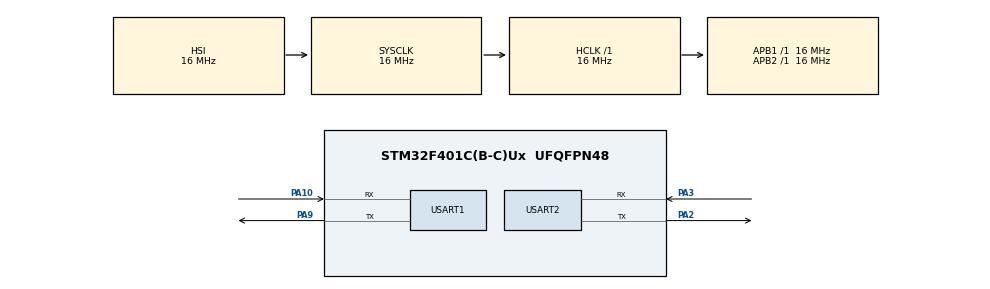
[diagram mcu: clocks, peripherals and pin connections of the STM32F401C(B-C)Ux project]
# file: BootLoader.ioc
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Mcu.Family=STM32F4
Mcu.Name=STM32F401C(B-C)Ux
Mcu.Package=UFQFPN48
NVIC.PriorityGroup=NVIC_PRIORITYGROUP_4
PA10.Mode=Asynchronous
PA10.Signal=USART1_RX
PA2.Mode=Asynchronous
PA2.Signal=USART2_TX
PA3.Mode=Asynchronous
PA3.Signal=USART2_RX
PA9.Mode=Asynchronous
PA9.Signal=USART1_TX
ProjectManager.HeapSize=0x200
ProjectManager.StackSize=0x400
ProjectManager.TargetToolchain=STM32CubeIDE
RCC.AHBFreq_Value=16000000
RCC.APB1Freq_Value=16000000
RCC.APB2Freq_Value=16000000
RCC.CortexFreq_Value=16000000
RCC.HSE_VALUE=25000000
RCC.HSI_VALUE=16000000
RCC.LSE_VALUE=32768
RCC.SYSCLKFreq_VALUE=16000000
RCC.VCOOutputFreq_Value=192000000
USART1.VirtualMode=VM_ASYNC
USART2.VirtualMode=VM_ASYNC
VP_CRC_VS_CRC.Mode=CRC_Activate
board=custom

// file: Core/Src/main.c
/* USER CODE BEGIN Header */
/**
  ******************************************************************************
  * @file           : main.c
  * @brief          : Main program body
  ******************************************************************************
  * @attention
  *
  * Copyright (c) 2024 STMicroelectronics.
  * All rights reserved.
  *
  * This software is licensed under terms that can be found in the LICENSE file
  * in the root directory of this software component.
  * If no LICENSE file comes with this software, it is provided AS-IS.
  *
  ******************************************************************************
  */
/* USER CODE END Header */
#include "main.h"

/* USER CODE BEGIN PM */
#define FLASH_SECTOR2_ADDRESS		0x08008000
/* USER CODE END PM */

CRC_HandleTypeDef hcrc;

UART_HandleTypeDef huart1;
UART_HandleTypeDef huart2;

void SystemClock_Config(void);
static void MX_GPIO_Init(void);
static void MX_CRC_Init(void);
static void MX_USART1_UART_Init(void);
static void MX_USART2_UART_Init(void);

int main(void)
{

  /* USER CODE BEGIN 1 */
	  char fatma[]="FatmaEzzatAbdelaziz\r\n";
	  HAL_Init();

		GPIO_InitTypeDef sw={
					.Pin=GPIO_PIN_1,
					.Mode=GPIO_MODE_INPUT,
					.Pull=GPIO_PULLDOWN,
					.Speed=GPIO_SPEED_FREQ_MEDIUM
		};
  /* USER CODE END 1 */

  /* Reset of all peripherals, Initializes the Flash interface and the Systick. */
  HAL_Init();

  /* Configure the system clock */
  SystemClock_Config();
  /* Initialize all configured peripherals */
  MX_GPIO_Init();
  MX_CRC_Init();
  MX_USART1_UART_Init();
  MX_USART2_UART_Init();
  /* USER CODE BEGIN 2 */

  HAL_GPIO_Init(GPIOA,&sw);

   if(HAL_GPIO_ReadPin(GPIOA,GPIO_PIN_1)==1){
 	  Bootloader_UARTRead();
   }else{
 	  Bootloader_Jump_App();

   }
   while (1)
   {

 	  HAL_UART_Transmit(&huart2,(uint8_t*)fatma,sizeof(fatma),HAL_MAX_DELAY);
 	  HAL_Delay(1000);

   }
}
void Bootloader_UARTRead(){

	uint8_t commandPacket[255]={0};

	while(1){
		//Clear the command Packet every iteration
		memset(commandPacket,0,255);

		/*Step1: Read the first byte which includes the "length to follow"*/
		HAL_UART_Receive(&huart2, &commandPacket[0],1, HAL_MAX_DELAY);

		/*Step2: Read the rest of command, its size is the previous byte value*/
		HAL_UART_Receive(&huart2, &commandPacket[1],commandPacket[0] , HAL_MAX_DELAY);

		/*Step3: */
		switch(commandPacket[1]){

		case BL_GET_VERSION:
			BL_voidHandleGetVersionCmd(commandPacket);
			break;

		case BL_GET_HELP:
			BL_voidHandleGetHelpCmd(commandPacket);
			break;

		case BL_GET_CHIP_ID:
			BL_voidHandleGetChipIdCmd(commandPacket);
			break;

		case BL_GET_RDP_STATUS:
			BL_voidHandleRDPStatusCmd(commandPacket);
			break;

		case BL_GOTO_ADDRESS:
			BL_voidHandleGoToAddressCmd(commandPacket);
			break;

		case BL_FLASH_ERASE:
			BL_voidHandleFlashEraseCmd(commandPacket);
			break;

		case BL_MEMEORY_WRITE:
			BL_voidHandleMemeoryWriteCmd(commandPacket);
			break;

		default:	/*Invalid Command from Host*/

		}
	}

}
void Bootloader_Jump_App(){

	/*
	 * 1-Get the address of User app to jump on it
	 * but before that we need to initialize the stack pointer of User application
	 * By software
	 * */
	//Pointer to func that points to APP_ResetHandler
	void (*App_ResetHandler)(void);

	//Get the value of the first location on the vector table
	uint32_t Local_MSP =*((volatile uint32_t *)(FLASH_SECTOR2_ADDRESS));

	//Assign it in MSP to initialize the stack by assembly
	__asm volatile("MSR MSP, %0"::"r"(Local_MSP));

	//Get the value of the second location on the vector table
	uint32_t RESET_HANDLER_ADD	=*((volatile uint32_t *)(FLASH_SECTOR2_ADDRESS+4));
	App_ResetHandler =(void *) RESET_HANDLER_ADD;

	//Jump on Reset Handler of the Application = start up code
 	App_ResetHandler();
}

void SystemClock_Config(void)
{
  RCC_OscInitTypeDef RCC_OscInitStruct = {0};
  RCC_ClkInitTypeDef RCC_ClkInitStruct = {0};

  /** Configure the main internal regulator output voltage
  */
  __HAL_RCC_PWR_CLK_ENABLE();
  __HAL_PWR_VOLTAGESCALING_CONFIG(PWR_REGULATOR_VOLTAGE_SCALE2);

  /** Initializes the RCC Oscillators according to the specified parameters
  * in the RCC_OscInitTypeDef structure.
  */
  RCC_OscInitStruct.OscillatorType = RCC_OSCILLATORTYPE_HSI;
  RCC_OscInitStruct.HSIState = RCC_HSI_ON;
  RCC_OscInitStruct.HSICalibrationValue = RCC_HSICALIBRATION_DEFAULT;
  RCC_OscInitStruct.PLL.PLLState = RCC_PLL_NONE;
  if (HAL_RCC_OscConfig(&RCC_OscInitStruct) != HAL_OK)
  {
    Error_Handler();
  }

  /** Initializes the CPU, AHB and APB buses clocks
  */
  RCC_ClkInitStruct.ClockType = RCC_CLOCKTYPE_HCLK|RCC_CLOCKTYPE_SYSCLK
                              |RCC_CLOCKTYPE_PCLK1|RCC_CLOCKTYPE_PCLK2;
  RCC_ClkInitStruct.SYSCLKSource = RCC_SYSCLKSOURCE_HSI;
  RCC_ClkInitStruct.AHBCLKDivider = RCC_SYSCLK_DIV1;
  RCC_ClkInitStruct.APB1CLKDivider = RCC_HCLK_DIV1;
  RCC_ClkInitStruct.APB2CLKDivider = RCC_HCLK_DIV1;

  if (HAL_RCC_ClockConfig(&RCC_ClkInitStruct, FLASH_LATENCY_0) != HAL_OK)
  {
    Error_Handler();
  }
}

static void MX_CRC_Init(void)
{

  hcrc.Instance = CRC;
  if (HAL_CRC_Init(&hcrc) != HAL_OK)
  {
    Error_Handler();
  }

}

static void MX_USART1_UART_Init(void)
{

  huart1.Instance = USART1;
  huart1.Init.BaudRate = 115200;
  huart1.Init.WordLength = UART_WORDLENGTH_8B;
  huart1.Init.StopBits = UART_STOPBITS_1;
  huart1.Init.Parity = UART_PARITY_NONE;
  huart1.Init.Mode = UART_MODE_TX_RX;
  huart1.Init.HwFlowCtl = UART_HWCONTROL_NONE;
  huart1.Init.OverSampling = UART_OVERSAMPLING_16;
  if (HAL_UART_Init(&huart1) != HAL_OK)
  {
    Error_Handler();
  }

}

static void MX_USART2_UART_Init(void)
{

  huart2.Instance = USART2;
  huart2.Init.BaudRate = 115200;
  huart2.Init.WordLength = UART_WORDLENGTH_8B;
  huart2.Init.StopBits = UART_STOPBITS_1;
  huart2.Init.Parity = UART_PARITY_NONE;
  huart2.Init.Mode = UART_MODE_TX_RX;
  huart2.Init.HwFlowCtl = UART_HWCONTROL_NONE;
  huart2.Init.OverSampling = UART_OVERSAMPLING_16;
  if (HAL_UART_Init(&huart2) != HAL_OK)
  {
    Error_Handler();
  }

}

static void MX_GPIO_Init(void)
{

  /* GPIO Ports Clock Enable */
  __HAL_RCC_GPIOA_CLK_ENABLE();

}

void Error_Handler(void)
{
  __disable_irq();
  while (1)
  {
  }
}
